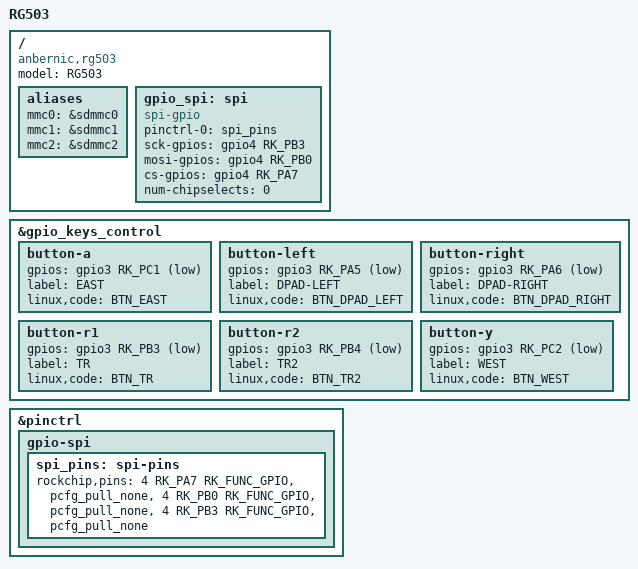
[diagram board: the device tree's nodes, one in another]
// SPDX-License-Identifier: (GPL-2.0+ OR MIT)

/dts-v1/;

#include <dt-bindings/gpio/gpio.h>
#include <dt-bindings/input/linux-event-codes.h>
#include <dt-bindings/pinctrl/rockchip.h>
#include "rk3566-anbernic-rgxx3.dtsi"

/ {
	model = "RG503";
	compatible = "anbernic,rg503", "rockchip,rk3566";

	aliases {
		mmc0 = &sdmmc0;
		mmc1 = &sdmmc1;
		mmc2 = &sdmmc2;
	};

	gpio_spi: spi {
		compatible = "spi-gpio";
		pinctrl-names = "default";
		pinctrl-0 = <&spi_pins>;
		#address-cells = <1>;
		#size-cells = <0>;

		sck-gpios = <&gpio4 RK_PB3 GPIO_ACTIVE_HIGH>;
		mosi-gpios = <&gpio4 RK_PB0 GPIO_ACTIVE_HIGH>;
		cs-gpios = <&gpio4 RK_PA7 GPIO_ACTIVE_HIGH>;
		num-chipselects = <0>;
	};
};

&gpio_keys_control {
	button-a {
		gpios = <&gpio3 RK_PC1 GPIO_ACTIVE_LOW>;
		label = "EAST";
		linux,code = <BTN_EAST>;
	};

	button-left {
		gpios = <&gpio3 RK_PA5 GPIO_ACTIVE_LOW>;
		label = "DPAD-LEFT";
		linux,code = <BTN_DPAD_LEFT>;
	};

	button-right {
		gpios = <&gpio3 RK_PA6 GPIO_ACTIVE_LOW>;
		label = "DPAD-RIGHT";
		linux,code = <BTN_DPAD_RIGHT>;
	};

	button-r1 {
		gpios = <&gpio3 RK_PB3 GPIO_ACTIVE_LOW>;
		label = "TR";
		linux,code = <BTN_TR>;
	};

	button-r2 {
		gpios = <&gpio3 RK_PB4 GPIO_ACTIVE_LOW>;
		label = "TR2";
		linux,code = <BTN_TR2>;
	};

	button-right {
		gpios = <&gpio3 RK_PA6 GPIO_ACTIVE_LOW>;
		label = "DPAD-RIGHT";
		linux,code = <BTN_DPAD_RIGHT>;
	};

	button-y {
		gpios = <&gpio3 RK_PC2 GPIO_ACTIVE_LOW>;
		label = "WEST";
		linux,code = <BTN_WEST>;
	};
};

&pinctrl {
	gpio-spi {
		spi_pins: spi-pins {
			rockchip,pins =
				<4 RK_PA7 RK_FUNC_GPIO &pcfg_pull_none>,
				<4 RK_PB0 RK_FUNC_GPIO &pcfg_pull_none>,
				<4 RK_PB3 RK_FUNC_GPIO &pcfg_pull_none>;
		};
	};
};
